# USB0_VBP2AHB_WRAP_CONTROLLER_VBP_USB3_CORE_OPER register map
Vendor: Texas Instruments
Peripheral module from a debugger description file (folder J722S).
Registers are 32-bit, read-write, reset 0x0 unless marked. A register's access mark holds for its fields unless they carry their own. Offsets are as the file gives them; lines under a group give offsets from that group; [hi:lo] are bit positions; {n}, {i} and the like mark numbered series; 'fields as' and 'values as' point back to an identical list; <NAME> marks a mode.

## USB0_VBP2AHB_WRAP_CONTROLLER_VBP_USB3_CORE_OPER
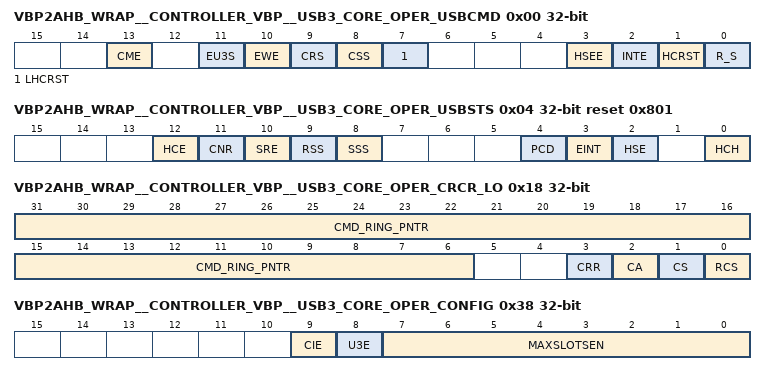
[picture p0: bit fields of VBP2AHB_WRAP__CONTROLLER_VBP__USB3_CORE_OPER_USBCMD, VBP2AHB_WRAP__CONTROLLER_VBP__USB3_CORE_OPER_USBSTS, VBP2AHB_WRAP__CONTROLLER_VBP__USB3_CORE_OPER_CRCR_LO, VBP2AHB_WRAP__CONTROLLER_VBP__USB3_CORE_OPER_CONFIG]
0x00 VBP2AHB_WRAP__CONTROLLER_VBP__USB3_CORE_OPER_USBCMD — USB Command Register For a description of this standard USB register field see the eXtensible Host Controller Interface for Universal Serial Bus (USB) Specification 3.0.
  [13] CME — CEM Enable For a description of this standard USB register field, see the eXtensible Host Controller Interface for Universal Serial Bus [USB] Specification 3.0.
  [11] EU3S — EU3S For a description of this standard USB register field, see the eXtensible Host Controller Interface for Universal Serial Bus [USB] Specification 3.0.
  [10] EWE — EWE For a description of this standard USB register field, see the eXtensible Host Controller Interface for Universal Serial Bus [USB] Specification 3.0.
  [9] CRS — Controller Restore State This command is similar to the USBCMD.CRS bit in host mode and initiates the restore process. When software sets this bit to '1', the controller immediately sets DSTS.RSS to '1'. When the controller has finished the restore process, it sets DSTS.RSS to '0'. Note: When read, this field always returns '0'.
  [8] CSS — Controller Save State This command is similar to the USBCMD.CSS bit in host mode and initiates the save process. When software sets this bit to '1', the controller immediately sets DSTS.SSS to '1'. When the controller has finished the save process, it sets DSTS.SSS to '0'. Note: When read, this field always returns '0'.
  [7] LHCRST — Light Host Controller Reset For a description of this standard USB register field, see the eXtensible Host Controller Interface for Universal Serial Bus [USB] Specification 3.0. The following bits reset the internal logic of the host controller. Under soft reset, some CSR accesses may fail [Timeout]. - HCRST - LHCRST Bit Bash register testing is not recommended.
  [3] HSEE — HSEE For a description of this standard USB register field, see the eXtensible Host Controller Interface for Universal Serial Bus [USB] Specification 3.0.
  [2] INTE — INTE For a description of this standard USB register field, see the eXtensible Host Controller Interface for Universal Serial Bus [USB] Specification 3.0.
  [1] HCRST — HCRST The following bits reset the internal logic of the host controller. Under soft reset, some CSR accesses may fail [Timeout]. - HCRST - LHCRST Bit Bash register testing is not recommended.
  [0] R_S — R_S For a description of this standard USB register field, see the eXtensible Host Controller Interface for Universal Serial Bus [USB] Specification 3.0. Due to side-effects this reguster field is not recommended for Bit-Bash testing.
0x04 VBP2AHB_WRAP__CONTROLLER_VBP__USB3_CORE_OPER_USBSTS access not given reset 0x801 — USB Status Register Bit Definitions For a description of this standard USB register field, see the eXtensible Host Controller Interface for Universal Serial Bus (USB) Specification 3.0.
  [12] HCE ro — Host Controller Error [HCE] - RO Default = 0. '0' = No internal xHC error conditions exist and '1' = Internal xHC error condition. This flag must be set to indicate that an internal error condition has been detected which requires software to reset and reinitialize the xHC. Refer to section 4.24.1 of the Databook for more information.
  [11] CNR ro — Controller Not Ready [CNR] - RO Default = '1'. '0' = Ready and '1' = Not Ready. Software must not write to thes Doorbell or Operational register of the xHC, other than the USBSTS register, until CNR = '0'. This flag is set by the xHC after a Chip Hardware Reset and cleared when the xHC is ready to begin accepting register writes. This flag remains cleared ['0'] until the next Chip Hardware Reset.
  [10] SRE — Save/Restore Error This bit is currently not supported. (access R/W1TC)
  [9] RSS ro — Restore State Status This bit is similar to the USBSTS.RSS in host mode. When the controller has finished the restore process, it completes the command by setting DSTS.RSS to '0'.
  [8] SSS ro — Save State Status This bit is similar to the USBSTS.SSS in host mode. When the controller has finished the save process, it completes the command by setting DSTS.SSS to '0'.
  [4] PCD — Reset Value for PCD (access R/W1TC)
  [3] EINT — Reset Value for EINT (access R/W1TC)
  [2] HSE — HSE For a description of this standard USB register field, see the eXtensible Host Controller Interface for Universal Serial Bus [USB] Specification 3.0.. (access R/W1TC)
  [0] HCH ro — HCH For a description of this standard USB register field, see the eXtensible Host Controller Interface for Universal Serial Bus [USB] Specification 3.0.
0x08 VBP2AHB_WRAP__CONTROLLER_VBP__USB3_CORE_OPER_PAGESIZE ro reset 0x1 — Page Size Register Bit Definitions Use this register to enable or disable the reporting of specific USB Device Notification Transaction Packets being received. A Notification Enable (Nx, where x = 0 to 15) flag is defined for each of the 16 possible device notification types. If a flag is set for a specific notification type, a Device Notification Event is generated when the respective notification packet is received. After reset, all notifications are disabled. Refer to section 6.4.2.7 of the Databook for more information. This register is written as a Dword. Byte writes produce undefined results.
  [15:0] PAGE_SIZE
0x14 VBP2AHB_WRAP__CONTROLLER_VBP__USB3_CORE_OPER_DNCTRL — Device Notification Register Bit Definitions For a description of this standard USB register field see the eXtensible Host Controller Interface for Universal Serial Bus (USB) Specification 3.0.
  [15:0] N0_N15 — N0_N15 For a description of this standard USB register field see the eXtensible Host Controller Interface for Universal Serial Bus [USB] Specification 3.0.
0x18 VBP2AHB_WRAP__CONTROLLER_VBP__USB3_CORE_OPER_CRCR_LO access per field — CRCR_LO For a description of this standard USB register field, see the eXtensible Host Controller Interface for Universal Serial Bus (USB) Specification 3.0.
  [31:6] CMD_RING_PNTR wo — CMD_RING_PNTR For a description of this standard USB register field, see the eXtensible Host Controller Interface for Universal Serial Bus [USB] Specification 3.0.
  [3] CRR ro — CRR For a description of this standard USB register field, see the eXtensible Host Controller Interface for Universal Serial Bus [USB] Specification 3.0.
  [2] CA wo — CA For a description of this standard USB register field, see the eXtensible Host Controller Interface for Universal Serial Bus [USB] Specification 3.0.
  [1] CS wo — CS For a description of this standard USB register field, see the eXtensible Host Controller Interface for Universal Serial Bus [USB] Specification 3.0.
  [0] RCS wo — RCS For a description of this standard USB register field, see the eXtensible Host Controller Interface for Universal Serial Bus [USB] Specification 3.0.
0x1C VBP2AHB_WRAP__CONTROLLER_VBP__USB3_CORE_OPER_CRCR_HI wo — CRCR_HI
  [31:0] CMD_RING_PNTR — COMMAND_RING_POINTER Reading this field always returns '0'. For a description of this standard USB register field, see the eXtensible Host Controller Interface for Universal Serial Bus [USB] Specification 3.0.
0x30 VBP2AHB_WRAP__CONTROLLER_VBP__USB3_CORE_OPER_DCBAAP_LO — DCBAAP_LO
  [31:6] DEVICE_CONTEXT_BAAP — DEVICE_CONTEXT_BAAP For a description of this standard USB register field, see the eXtensible Host Controller Interface for Universal Serial Bus [USB] Specification 3.0.
0x34 VBP2AHB_WRAP__CONTROLLER_VBP__USB3_CORE_OPER_DCBAAP_HI — DCBAAP_HI For a description of this standard USB register field, see the eXtensible Host Controller Interface for Universal Serial Bus (USB) Specification 3.0.
  [31:0] DEVICE_CONTEXT_BAAP
0x38 VBP2AHB_WRAP__CONTROLLER_VBP__USB3_CORE_OPER_CONFIG — Configure Register Bit Definitions This register is in the Aux Power well. It is only reset by platform hardware during a cold reset or in response to a Host Controller Reset (HCRST). The initial conditions of a port are described in section 4.19 of the Databook.
  [9] CIE — Configuration Information Enable For a description of this standard USB register field, see the eXtensible Host Controller Interface for Universal Serial Bus [USB] Specification 3.0.
  [8] U3E — U3 Entry Enable For a description of this standard USB register field, see the eXtensible Host Controller Interface for Universal Serial Bus [USB] Specification 3.0.
  [7:0] MAXSLOTSEN — MAXSLOTSEN For a description of this standard USB register field, see the eXtensible Host Controller Interface for Universal Serial Bus [USB] Specification 3.0.
